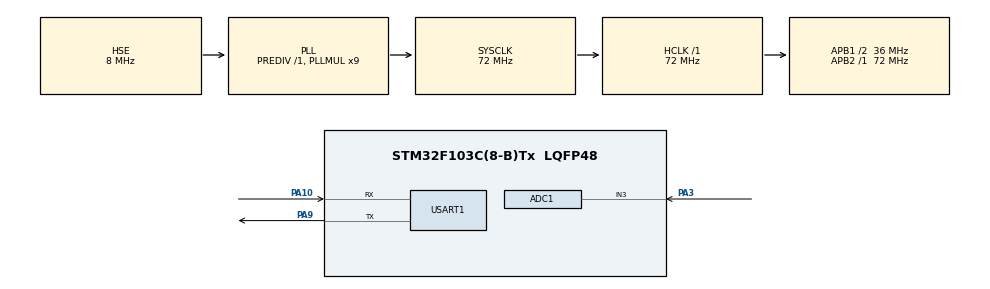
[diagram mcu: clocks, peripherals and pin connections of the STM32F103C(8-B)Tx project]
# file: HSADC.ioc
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ADC1.Channel-0\#ChannelRegularConversion=ADC_CHANNEL_3
ADC1.ExternalTrigConv=ADC_EXTERNALTRIGCONV_T3_TRGO
ADC1.NbrOfConversionFlag=1
ADC1.Rank-0\#ChannelRegularConversion=1
ADC1.SamplingTime-0\#ChannelRegularConversion=ADC_SAMPLETIME_13CYCLES_5
ADC1.master=1
Dma.ADC1.0.Direction=DMA_PERIPH_TO_MEMORY
Dma.ADC1.0.Instance=DMA1_Channel1
Dma.ADC1.0.MemDataAlignment=DMA_MDATAALIGN_HALFWORD
Dma.ADC1.0.MemInc=DMA_MINC_ENABLE
Dma.ADC1.0.Mode=DMA_CIRCULAR
Dma.ADC1.0.PeriphDataAlignment=DMA_PDATAALIGN_HALFWORD
Dma.ADC1.0.PeriphInc=DMA_PINC_DISABLE
Dma.ADC1.0.Priority=DMA_PRIORITY_MEDIUM
Dma.Request0=ADC1
Dma.Request1=USART1_RX
Dma.Request2=USART1_TX
Dma.USART1_RX.1.Direction=DMA_PERIPH_TO_MEMORY
Dma.USART1_RX.1.Instance=DMA1_Channel5
Dma.USART1_RX.1.MemDataAlignment=DMA_MDATAALIGN_BYTE
Dma.USART1_RX.1.MemInc=DMA_MINC_ENABLE
Dma.USART1_RX.1.Mode=DMA_NORMAL
Dma.USART1_RX.1.PeriphDataAlignment=DMA_PDATAALIGN_BYTE
Dma.USART1_RX.1.PeriphInc=DMA_PINC_DISABLE
Dma.USART1_RX.1.Priority=DMA_PRIORITY_LOW
Dma.USART1_TX.2.Direction=DMA_MEMORY_TO_PERIPH
Dma.USART1_TX.2.Instance=DMA1_Channel4
Dma.USART1_TX.2.MemDataAlignment=DMA_MDATAALIGN_BYTE
Dma.USART1_TX.2.MemInc=DMA_MINC_ENABLE
Dma.USART1_TX.2.Mode=DMA_NORMAL
Dma.USART1_TX.2.PeriphDataAlignment=DMA_PDATAALIGN_BYTE
Dma.USART1_TX.2.PeriphInc=DMA_PINC_DISABLE
Dma.USART1_TX.2.Priority=DMA_PRIORITY_LOW
Mcu.Family=STM32F1
Mcu.Name=STM32F103C(8-B)Tx
Mcu.Package=LQFP48
NVIC.DMA1_Channel1_IRQn=true\:0\:0\:false\:false\:true\:false\:true\:true
NVIC.DMA1_Channel4_IRQn=true\:0\:0\:false\:false\:true\:false\:true\:true
NVIC.DMA1_Channel5_IRQn=true\:0\:0\:false\:false\:true\:false\:true\:true
NVIC.PriorityGroup=NVIC_PRIORITYGROUP_4
NVIC.TIM4_IRQn=true\:15\:0\:false\:false\:true\:false\:true\:true
NVIC.TimeBase=TIM4_IRQn
NVIC.TimeBaseIP=TIM4
NVIC.USART1_IRQn=true\:0\:0\:false\:false\:true\:false\:true\:true
PA10.Mode=Asynchronous
PA10.Signal=USART1_RX
PA13.Mode=Serial_Wire
PA13.Signal=SYS_JTMS-SWDIO
PA14.Mode=Serial_Wire
PA14.Signal=SYS_JTCK-SWCLK
PA3.Signal=ADCx_IN3
PA9.Mode=Asynchronous
PA9.Signal=USART1_TX
PD0-OSC_IN.Mode=HSE-External-Oscillator
PD0-OSC_IN.Signal=RCC_OSC_IN
PD1-OSC_OUT.Mode=HSE-External-Oscillator
PD1-OSC_OUT.Signal=RCC_OSC_OUT
ProjectManager.HeapSize=0x200
ProjectManager.StackSize=0x400
ProjectManager.TargetToolchain=MDK-ARM V5.32
RCC.ADCPresc=RCC_ADCPCLK2_DIV6
RCC.AHBFreq_Value=72000000
RCC.APB1CLKDivider=RCC_HCLK_DIV2
RCC.APB1Freq_Value=36000000
RCC.APB1TimFreq_Value=72000000
RCC.APB2Freq_Value=72000000
RCC.APB2TimFreq_Value=72000000
RCC.HCLKFreq_Value=72000000
RCC.PLLMUL=RCC_PLL_MUL9
RCC.PLLSourceVirtual=RCC_PLLSOURCE_HSE
RCC.SYSCLKFreq_VALUE=72000000
RCC.SYSCLKSource=RCC_SYSCLKSOURCE_PLLCLK
RCC.USBFreq_Value=72000000
SH.ADCx_IN3.0=ADC1_IN3,IN3
TIM3.Period=9
TIM3.Prescaler=72-1
TIM3.TIM_MasterOutputTrigger=TIM_TRGO_UPDATE
USART1.VirtualMode=VM_ASYNC
VP_SYS_VS_tim4.Mode=TIM4
VP_TIM3_VS_ClockSourceINT.Mode=Internal
board=custom

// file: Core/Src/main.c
/* USER CODE BEGIN Header */
/**
  ******************************************************************************
  * @file           : main.c
  * @brief          : Main program body
  ******************************************************************************
  * @attention
  *
  * Copyright (c) 2026 STMicroelectronics.
  * All rights reserved.
  *
  * This software is licensed under terms that can be found in the LICENSE file
  * in the root directory of this software component.
  * If no LICENSE file comes with this software, it is provided AS-IS.
  *
  ******************************************************************************
  */
/* USER CODE END Header */
#include "main.h"
#include "adc.h"
#include "dma.h"
#include "tim.h"
#include "usart.h"
#include "gpio.h"

/* USER CODE BEGIN Includes */
#include <stdio.h>
#include <string.h>
#include "signal_process.h"
/* USER CODE END Includes */

/* USER CODE BEGIN PD */
#define SAMPLE_BUFFER_SIZE 8000
#define ADC_MAX_VALUE 4095
#define ADC_REF_VOLTAGE 3.3f
#define SAMPLING_RATE_HZ 500000.0f
#define COLLECTION_INTERVAL_MS 1000
/* USER CODE END PD */

/* USER CODE BEGIN PV */
uint16_t adc_buffer[SAMPLE_BUFFER_SIZE];
volatile uint8_t collection_ready = 0;
volatile uint32_t last_collection_time = 0;
/* USER CODE END PV */

void SystemClock_Config(void);
/* USER CODE BEGIN PFP */
void Process_ADC_Data_Once(void);
/* USER CODE END PFP */

/* USER CODE BEGIN 0 */
void Process_ADC_Data_Once(void)
{
  SignalAnalysisResult sig_result = Analyze_Signal_ZC(adc_buffer, SAMPLE_BUFFER_SIZE, SAMPLING_RATE_HZ, ADC_REF_VOLTAGE);
  char sig_output[128];
  int len = sprintf(sig_output, "[1s Collection] Freq: %.2f Hz, Vpp: %.3f V, Vmin: %.3f V, Vmax: %.3f V\r\n",
          sig_result.frequency, sig_result.vpp, sig_result.vmin, sig_result.vmax);
  HAL_UART_Transmit(&huart1, (uint8_t*)sig_output, len, HAL_MAX_DELAY);
}
/* USER CODE END 0 */

int main(void)
{

  /* MCU Configuration--------------------------------------------------------*/

  /* Reset of all peripherals, Initializes the Flash interface and the Systick. */
  HAL_Init();

  /* Configure the system clock */
  SystemClock_Config();

  /* Initialize all configured peripherals */
  MX_GPIO_Init();
  MX_DMA_Init();
  MX_ADC1_Init();
  MX_TIM3_Init();
  MX_USART1_UART_Init();
  /* USER CODE BEGIN 2 */
  if (HAL_ADCEx_Calibration_Start(&hadc1) == HAL_OK)
  {
    char calib_msg[] = "ADC Calibration Complete\r\n";
    HAL_UART_Transmit(&huart1, (uint8_t*)calib_msg, strlen(calib_msg), HAL_MAX_DELAY);
  }
  UART_Start_Receive();

  char init_msg[] = "System Initialized. 100kHz Sampling, 8000pts/sec\r\n";
  HAL_UART_Transmit(&huart1, (uint8_t*)init_msg, strlen(init_msg), HAL_MAX_DELAY);

  HAL_ADC_Start_DMA(&hadc1, (uint32_t*)adc_buffer, SAMPLE_BUFFER_SIZE);
  HAL_TIM_Base_Start(&htim3);

  last_collection_time = g_systick_counter;
  /* USER CODE END 2 */

  /* Infinite loop */
  /* USER CODE BEGIN WHILE */
  while (1)
  {
    UART_Process_Command();

    if ((g_systick_counter - last_collection_time) >= COLLECTION_INTERVAL_MS)
    {
      last_collection_time = g_systick_counter;
      Process_ADC_Data_Once();
    }
    /* USER CODE END WHILE */

  }
}

void SystemClock_Config(void)
{
  RCC_OscInitTypeDef RCC_OscInitStruct = {0};
  RCC_ClkInitTypeDef RCC_ClkInitStruct = {0};
  RCC_PeriphCLKInitTypeDef PeriphClkInit = {0};

  /** Initializes the RCC Oscillators according to the specified parameters
  * in the RCC_OscInitTypeDef structure.
  */
  RCC_OscInitStruct.OscillatorType = RCC_OSCILLATORTYPE_HSE;
  RCC_OscInitStruct.HSEState = RCC_HSE_ON;
  RCC_OscInitStruct.HSEPredivValue = RCC_HSE_PREDIV_DIV1;
  RCC_OscInitStruct.HSIState = RCC_HSI_ON;
  RCC_OscInitStruct.PLL.PLLState = RCC_PLL_ON;
  RCC_OscInitStruct.PLL.PLLSource = RCC_PLLSOURCE_HSE;
  RCC_OscInitStruct.PLL.PLLMUL = RCC_PLL_MUL9;
  if (HAL_RCC_OscConfig(&RCC_OscInitStruct) != HAL_OK)
  {
    Error_Handler();
  }

  /** Initializes the CPU, AHB and APB buses clocks
  */
  RCC_ClkInitStruct.ClockType = RCC_CLOCKTYPE_HCLK|RCC_CLOCKTYPE_SYSCLK
                              |RCC_CLOCKTYPE_PCLK1|RCC_CLOCKTYPE_PCLK2;
  RCC_ClkInitStruct.SYSCLKSource = RCC_SYSCLKSOURCE_PLLCLK;
  RCC_ClkInitStruct.AHBCLKDivider = RCC_SYSCLK_DIV1;
  RCC_ClkInitStruct.APB1CLKDivider = RCC_HCLK_DIV2;
  RCC_ClkInitStruct.APB2CLKDivider = RCC_HCLK_DIV1;

  if (HAL_RCC_ClockConfig(&RCC_ClkInitStruct, FLASH_LATENCY_2) != HAL_OK)
  {
    Error_Handler();
  }
  PeriphClkInit.PeriphClockSelection = RCC_PERIPHCLK_ADC;
  PeriphClkInit.AdcClockSelection = RCC_ADCPCLK2_DIV6;
  if (HAL_RCCEx_PeriphCLKConfig(&PeriphClkInit) != HAL_OK)
  {
    Error_Handler();
  }
}

void HAL_TIM_PeriodElapsedCallback(TIM_HandleTypeDef *htim)
{
  if (htim->Instance == TIM4)
  {
    HAL_IncTick();
  }
  /* USER CODE BEGIN Callback 1 */
  if (htim->Instance == TIM4)
  {
    g_systick_counter++;
  }
  /* USER CODE END Callback 1 */
}

void Error_Handler(void)
{
  __disable_irq();
  while (1)
  {
  }
}
